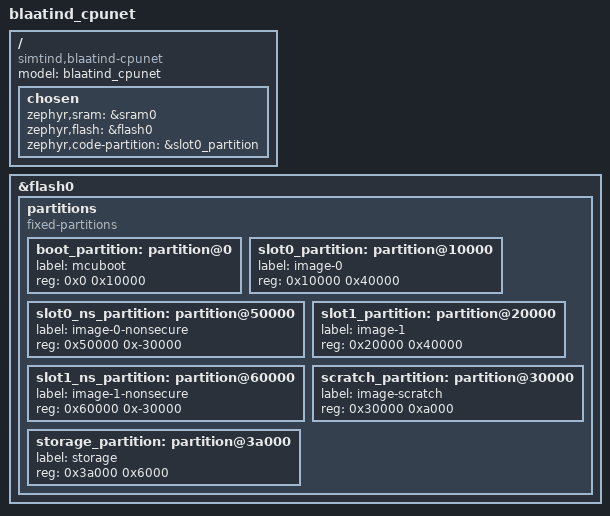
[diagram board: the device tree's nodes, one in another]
// Copyright (c) 2022 Nordic Semiconductor ASA
// SPDX-License-Identifier: Apache-2.0

/dts-v1/;
#include <nordic/nrf5340_cpunet_qkaa.dtsi>

/ {
	model = "blaatind_cpunet";
	compatible = "simtind,blaatind-cpunet";

	chosen {
		zephyr,sram = &sram0;
		zephyr,flash = &flash0;
		zephyr,code-partition = &slot0_partition;
	};
};

&flash0 {
	partitions {
		compatible = "fixed-partitions";
		#address-cells = <1>;
		#size-cells = <1>;

		boot_partition: partition@0 {
			label = "mcuboot";
			reg = <0x0 0x10000>;
		};
		slot0_partition: partition@10000 {
			label = "image-0";
			reg = <0x10000 0x40000>;
		};
		slot0_ns_partition: partition@50000 {
			label = "image-0-nonsecure";
			reg = <0x50000 0x-30000>;
		};
		slot1_partition: partition@20000 {
			label = "image-1";
			reg = <0x20000 0x40000>;
		};
		slot1_ns_partition: partition@60000 {
			label = "image-1-nonsecure";
			reg = <0x60000 0x-30000>;
		};
		scratch_partition: partition@30000 {
			label = "image-scratch";
			reg = <0x30000 0xa000>;
		};
		storage_partition: partition@3a000 {
			label = "storage";
			reg = <0x3a000 0x6000>;
		};
	};
};

